AUTOSAR XML (schema 00050)
package /Components
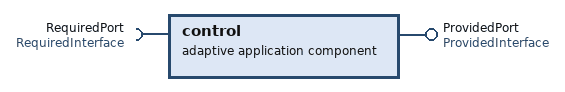
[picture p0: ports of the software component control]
  adaptive application sw component type control
    require port RequiredPort: queued-receiver-com-spec=data-element=AEB, required-interface=RequiredInterface
    provide port ProvidedPort: queued-sender-com-spec=data-element=Throttle, provided-interface=ProvidedInterface
